# RS1xxxx register map
Vendor: Silicon Lab Inc.; Series: ARMCM4; File version: 1.2
CPU: CM4 r1p0, little endian, MPU, FPU, 6 interrupt priority bits
Registers are 32-bit, read-write, reset 0x0 unless marked. A register's access mark holds for its fields unless they carry their own. Offsets are from the block's base; [hi:lo] are bit positions; {n}, {i} and the like mark numbered series; 'fields as' and 'values as' point back to an identical list.

## QSPI_2 (part 1 of 2) — The queued serial peripheral interface module provides a serial peripheral interface with queued transfer capability
Base 0x12040000
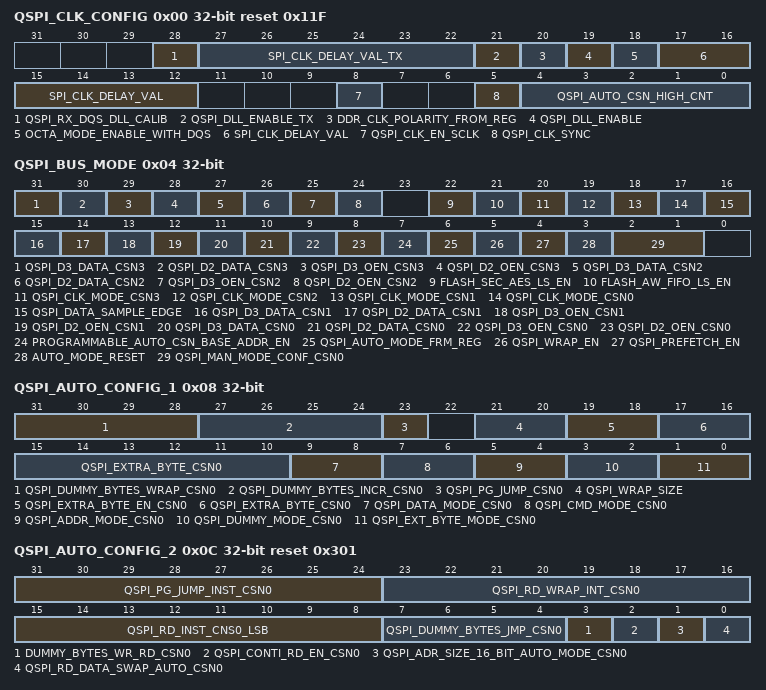
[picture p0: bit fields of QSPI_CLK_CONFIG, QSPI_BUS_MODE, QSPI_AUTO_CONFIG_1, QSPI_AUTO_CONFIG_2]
0x00 QSPI_CLK_CONFIG reset 0x11F — QSPI Clock Configuration Register
  [28] QSPI_RX_DQS_DLL_CALIB — Delay value programmed to TX QSPI DLL in write path. This delay is used to delay the qspi clock output according to the requirement
  [27:22] SPI_CLK_DELAY_VAL_TX — Delay value programmed to TX QSPI DLL in write path. This delay is used to delay the qspi clock output according to the requirement
  [21] QSPI_DLL_ENABLE_TX — Enable for TX QSPI DLL in write path. This is used in M4SS QSPI DDR pads to delay the qspi clock output. 0–DLL is disabled bypassed 1–DLL is enabled
    0=Disable (DLL is disabled/bypassed.); 1=Enable (DLL is enabled)
  [20] DDR_CLK_POLARITY_FROM_REG — Used this bit to sample the data at posedge negedge after interface FFs with internal qspi clock
    0=Disable (Sample at negedge); 1=Enable (Sample at posedge)
  [19] QSPI_DLL_ENABLE — Enable for RX QSPI DLL in read mode.This is used in M4SS QSPI DDR pads to delay the pad clock DQS input
    0=Disable (DLL is disabled/bypassed); 1=Enable (DLL is enabled)
  [18] OCTA_MODE_ENABLE_WITH_DQS — Enables SPI octa mode along with DQS in DDR mode
  [17:12] SPI_CLK_DELAY_VAL — Delay value programmed to RX QSPI DLL on read side. This delay is used to delay the pad clock/DQS according to the requirement
  [8] QSPI_CLK_EN_SCLK — QSPI clock enable for sclock
    0=Disable (Dynamic clock gating is enabled in side QSPI controller); 1=Enable (Full time clock is enabled for QSPI controller.)
  [5] QSPI_CLK_SYNC — If the clock frequency to FLASH(spi_clk) and QSPI(hclk) controller is same,this bit can be set to one to by-pass the syncros results in time consumption
    0=Disable (Sync logic is enabled); 1=Enable (Sync (synchros) logic is bypassed)
  [4:0] QSPI_AUTO_CSN_HIGH_CNT — Minimum SOC clock cycles, during which QSPI auto csn should be high between consecutive CSN assertions
0x04 QSPI_BUS_MODE
  [31] QSPI_D3_DATA_CSN3 — Value of SPI_IO3 in case of dual/single mode for chip select3 (cs_n3). It is used both in Auto and Manual Mode.
  [30] QSPI_D2_DATA_CSN3 — Value of SPI_IO2 in case of dual/single mode for chip select3 (cs_n3). It is used both in Auto and Manual Mode.
  [29] QSPI_D3_OEN_CSN3 — Direction Control for SPI_IO3 in case of dual/single mode for chip select3 (cs_n3). It is used both in Auto and Manual Mode.
  [28] QSPI_D2_OEN_CSN3 — Direction Control for SPI_IO2 in case of dual/single mode for chip select3 (cs_n3). It is used both in Auto and Manual Mode.
  [27] QSPI_D3_DATA_CSN2 — Value of SPI_IO3 in case of dual/single mode for chip select2 (cs_n2). It is used both in Auto and Manual Mode.
  [26] QSPI_D2_DATA_CSN2 — Value of SPI_IO2 in case of dual/single mode for chip select2 (cs_n2). It is used both in Auto and Manual Mode.
  [25] QSPI_D3_OEN_CSN2 — Direction Control for SPI_IO3 in case of dual/single mode for chip select2 (cs_n2). It is used both in Auto and Manual Mode.
  [24] QSPI_D2_OEN_CSN2 — Direction Control for SPI_IO2 in case of dual/single mode for chip select2 (cs_n2). It is used both in Auto and Manual Mode.
  [22] FLASH_SEC_AES_LS_EN — Qspi flash auto write fifo light sleep enable
  [21] FLASH_AW_FIFO_LS_EN — Qspi flash auto write fifo light sleep enable
  [20] QSPI_CLK_MODE_CSN3 — QSPI Clock Mode
    0=Mode 0, QSPI_CLK is low when QSPI_CS is high for chip select3 csn3; 1=Mode 3, QSPI_CLK is high when QSPI_CS is high for chip select3 csn3
  [19] QSPI_CLK_MODE_CSN2 — QSPI Clock Mode
    0=Mode 0 QSPI_CLK is low when QSPI_CS is high for chip select2 csn2; 1=Mode 3 QSPI_CLK is high when QSPI_CS is high for chip select2 csn2
  [18] QSPI_CLK_MODE_CSN1 — QSPI Clock Mode
    0=Mode 0, QSPI_CLK is low when QSPI_CS is high for chip select1 csn1; 1=Mode 3, QSPI_CLK is high when QSPI_CS is high for chip select1 csn1
  [17] QSPI_CLK_MODE_CSN0 — QSPI Clock Mode
    0=Mode 0, QSPI_CLK is low when QSPI_CS is high for chip select0 csn0; 1=Mode 3, QSPI_CLK is high when QSPI_CS is high for chip select0 csn0
  [16] QSPI_DATA_SAMPLE_EDGE — Samples MISO data on clock edges. This should be ZERO for mode3 clock.
    0=Disable (Pos edge of loop back spi_pad_clk. Use for low speed mode (sclk freq =< 40 MHz)); 1=Enable (Neg edge of loop back spi_pad_clk. Use for high speed mode (sclk freq >= 40 MHz))
  [15] QSPI_D3_DATA_CSN1 — Value of SPI_IO3 in case of dual/single mode for chip select1 (cs_n1). It is used both in Auto and Manual Mode.
  [14] QSPI_D2_DATA_CSN1 — Value of SPI_IO2 in case of dual/single mode for chip select1 (cs_n1). It is used both in Auto and Manual Mode.
  [13] QSPI_D3_OEN_CSN1 — Direction Control for SPI_IO3 in case of dual/single mode for chip select1 (cs_n1). It is used both in Auto and Manual Mode.
  [12] QSPI_D2_OEN_CSN1 — Direction Control for SPI_IO2 in case of dual/single mode for chip select1 (cs_n1). It is used both in Auto and Manual Mode.
  [11] QSPI_D3_DATA_CSN0 — Value of SPI_IO3 in case of dual/single mode for chip select0 csn0.It is used both in Auto and Manual Mode
  [10] QSPI_D2_DATA_CSN0 — Value of SPI_IO2 in case of dual/single mode for chip select0 csn0.It is used both in Auto and Manual Mode.
  [9] QSPI_D3_OEN_CSN0 — Direction Control for SPI_IO3 in case of dual/single mode for chip select0 csn0.It is used both in Auto and Manual Mode.
  [8] QSPI_D2_OEN_CSN0 — Direction Control for SPI_IO2 in case of dual/single mode for chip select0 csn0.It is used both in Auto and Manual Mode
  [7] PROGRAMMABLE_AUTO_CSN_BASE_ADDR_EN — Programmable auto csn mode enable
    1=Enable (Programmable auto csn mode is enabled.); 0=Disable (Programmable auto csn mode is diabled)
  [6] QSPI_AUTO_MODE_FRM_REG — QSPI Mode of Operation. This is valid only when HW_CTRLD_QSPI_MODE_CTRL is zero. Before switching from MANUAL to AUTO_MODE, MANUAL should be IDLE. During transition from AUTO_MODE to MANUAL_MODE(After resetting this bit to zero) we have to make sure AUTO mode operations should be completed by checking the STATUS bit in MANUAL_STATUS register[12] (0 - Idle).
    0=Disable (Manual Mode is selected); 1=Enable (Auto Mode is selected.)
  [5] QSPI_WRAP_EN — Model wrap is considered with this bit and uses wrap instruction to read from FLASH, loaded into corresponding auto_config (csn0, csn1) register. Note : Wrap mode is common in AUTO_MODE for both Flashes connected to csn0 and csn1.
    0=Disable (Wrap mode is disabled (AHB WRAP can be used).); 1=Enable (Wrap mode is enabled)
  [4] QSPI_PREFETCH_EN — Pre-fetch of data from the model which is connected to QSPI, automatically with out reading on AHB and is supplied to AHB, when address is matched with AHB read transaction address. Note : Pre-fetch mode is common in AUTO_MODE for both Flashes connected to csn0 and csn1.
    0=Disable (Pre-fetch mode is disabled.); 1=Enable (Pre-fetch mode is enabled)
  [3] AUTO_MODE_RESET — QSPI Auto controller reset. This is not a Self clearing bit
    0=Disable (Auto mode is active); 1=Enable (Auto mode is inactive(In soft-reset). Auto mode FIFO also get reset. Prefetch should be disabled while going to reset. The controller should be in normal (Not a HW_mode) Manual mode.)
  [2:1] QSPI_MAN_MODE_CONF_CSN0 — Configures the QSPI flash for Single/Dual/Quad mode operation in manual mode
    0=Single Mode; 1=Dual Mode; 2=Quad Mode
0x08 QSPI_AUTO_CONFIG_1 (reset mask 0xFF8FFFFF) — QSPI Auto Controller Configuration 1 Register
  [31:28] QSPI_DUMMY_BYTES_WRAP_CSN0 — Specifies the number of dummy bytes 0 to 7 for the selected SPI mode in case of wrap instruction
  [27:24] QSPI_DUMMY_BYTES_INCR_CSN0 — Specifies the number of dummy bytes 0 to 7 for the selected SPI mode
  [23] QSPI_PG_JUMP_CSN0 — Index Jump instruction
    0=Disable (Do not use Index jump instruction); 1=Enable (Use Index jump instruction specified by QSPI_PG_JUMP_INST)
  [21:20] QSPI_WRAP_SIZE — Qspi auto wrap size
  [19:18] QSPI_EXTRA_BYTE_EN_CSN0 — Value of the extra byte to be transmitted, if the extra byte mode is enabled
    0=Not transmit byte (Do not transmit extra byte.); 1=Transmit byte (Transmit Extra byte after address phase); 2=Transmit first nibble (Transmit only first nibble of the byte and maintain Hi-Z on the IO bus for next nibble)
  [17:10] QSPI_EXTRA_BYTE_CSN0 — Value of the extra byte to be transmitted, if the extra byte mode is enabled
  [9:8] QSPI_DATA_MODE_CSN0 — Mode of operation of QSPI in DATA phase
    0=SPI; 1=Dual SPI; 2=Quad SPI
  [7:6] QSPI_CMD_MODE_CSN0 — Mode of operation of QSPI in instruction phase
    0=SPI; 1=Dual SPI; 2=Quad SPI
  [5:4] QSPI_ADDR_MODE_CSN0 — Mode of operation of QSPI in instruction phase
    0=SPI; 1=Dual SPI; 2=Quad SPI
  [3:2] QSPI_DUMMY_MODE_CSN0 — Mode of operation of QSPI in instruction phase
    0=SPI; 1=Dual SPI; 2=Quad SPI
  [1:0] QSPI_EXT_BYTE_MODE_CSN0 — Mode of operation of QSPI in the extra byte phase
    0=SPI; 1=Dual SPI; 2=Quad SPI
0x0C QSPI_AUTO_CONFIG_2 reset 0x301 — QSPI Auto Controller Configuration 2 Register
  [31:24] QSPI_PG_JUMP_INST_CSN0 — Read instruction to be used, when Page jump is to be used
  [23:16] QSPI_RD_WRAP_INT_CSN0 — Read instruction to be used, when wrap mode is supported by QSPI flash
  [15:8] QSPI_RD_INST_CNS0_LSB — Read instruction LS byte to be used for the selected SPI modes and when wrap is not needed or supported.
  [7:4] QSPI_DUMMY_BYTES_JMP_CSN0 — Dummy cycles to be selected in case of JUMP
  [3] DUMMY_BYTES_WR_RD_CSN0 — Dummy bytes to the model to be read or to be write
    0=Disable (Dummy bytes will be read); 1=Enable (Dummy bytes to be write.)
  [2] QSPI_CONTI_RD_EN_CSN0 — Continuous read enable bit
    0=Disable (Continuous read disabled.); 1=Enable (Continuous read enabled.)
  [1] QSPI_ADR_SIZE_16_BIT_AUTO_MODE_CSN0 — Bit address sent to model
    0=Disable (24 bit address is sent to model); 1=Enable (16 Bit address is sent to model)
  [0] QSPI_RD_DATA_SWAP_AUTO_CSN0 — Auto read data
    0=Disable (Do not swap the read data in auto mode); 1=Enable (Swap the auto read data in auto mode)
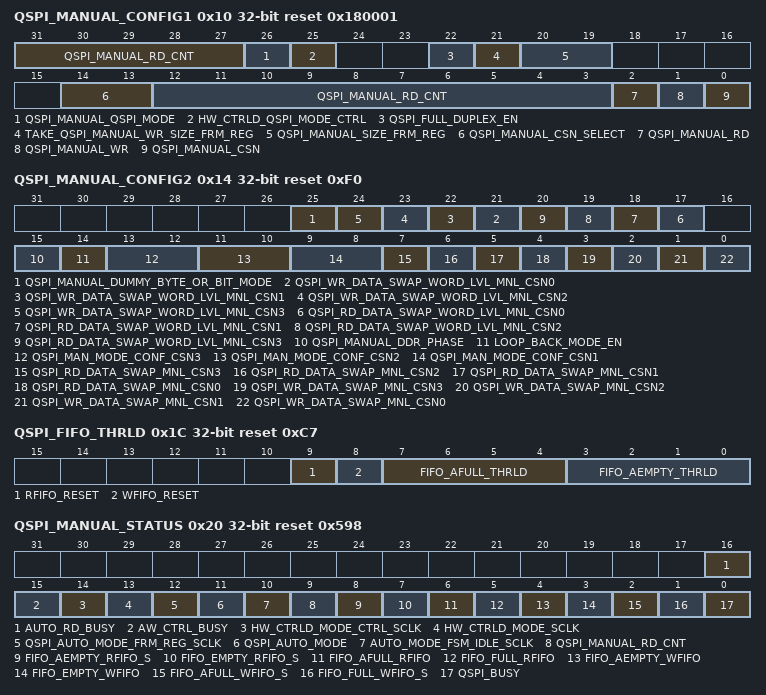
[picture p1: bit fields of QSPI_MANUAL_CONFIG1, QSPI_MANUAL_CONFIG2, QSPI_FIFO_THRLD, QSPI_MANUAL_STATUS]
0x10 QSPI_MANUAL_CONFIG1 reset 0x180001 — QSPI Manual Configuration 1 Register
  [31:27] QSPI_MANUAL_RD_CNT — Indicates total number of bytes or bits (depending on Qspi_manual_dummy_byte_or_bit_mode bit) to be read along with 12:3 bits of this register. Maximum length supported is 32k bytes.
  [26] QSPI_MANUAL_QSPI_MODE — Internally the priority is given to manual mode
    0=Disable (SPI mode); 1=Enable (Host SPI mode.)
  [25] HW_CTRLD_QSPI_MODE_CTRL — Hardware controlled qspi mode in between AUTO and manual
    0=Disable (Hardware control is disabled); 1=Enable (Hardware control is enabled.)
  [22] QSPI_FULL_DUPLEX_EN — Full duplex mode enable.
    0=Disable (Full duplex mode disabled.); 1=Enable (Full duplex mode enabled)
  [21] TAKE_QSPI_MANUAL_WR_SIZE_FRM_REG — QSPI take write size
    0=Disable (No action. Takes write size from fifo); 1=Enable (Take write size from Manual config register1)
  [20:19] QSPI_MANUAL_SIZE_FRM_REG — Manual reads and manual writes(If take_manual_size_from_reg bit is 1)
    0=1 Byte (8 – bit mode); 1=2 Bytes (16 – bit mode); 2=3 Bytes (24 – bit mode); 3=4 Bytes (32 – bit mode)
  [14:13] QSPI_MANUAL_CSN_SELECT — Indicates which CSn is valid. Can be programmable in manual mode. Note : In auto mode csn select is decoded from the address itself, AHB_addr [25:24].
  [12:3] QSPI_MANUAL_RD_CNT — Indicates total number of bytes to be read along with [31:27] bits of this register.Maximum length supported is 32k bytes
  [2] QSPI_MANUAL_RD — Read enable for manual mode when CS is low
  [1] QSPI_MANUAL_WR — Write enable for manual mode when CS is low
  [0] QSPI_MANUAL_CSN — SPI CS in manual mode
0x14 QSPI_MANUAL_CONFIG2 reset 0xF0 (reset mask 0xFFF) — QSPI Manual Configuration 2 Register
  [25] QSPI_MANUAL_DUMMY_BYTE_OR_BIT_MODE — Indicates qspi_manual_rd_cnt values are dummy bytes or bits in manual mode.It is used to provide proper dummy cycles in manual read mode.
    1=Enable (Dummy bits mode); 0=Disable (Dummy bytes mode)
  [n+21] QSPI_WR_DATA_SWAP_WORD_LVL_MNL_CSN{n} (n=0..3) — Set this bit for write data byte swapping within the word. It is valid only for octa ddr mode. It is valid for csn{n}.
  [n+17] QSPI_RD_DATA_SWAP_WORD_LVL_MNL_CSN{n} (n=0..3) — Set this bit for read data byte swapping within the word. It is valid only for octa ddr mode. It is valid for csn{n}.
  [15] QSPI_MANUAL_DDR_PHASE — DDR operations can be performed even in manual mode
    1=Enable (Manual mode DDR operation enabled.); 0=Disable (Manual mode DDR operation disabled)
  [14] LOOP_BACK_MODE_EN — Internal loop back test mode. When this is enabled, what ever data driven out will be sampled in to DOUT fifo.
  [13:12] QSPI_MAN_MODE_CONF_CSN3 — Configures the QSPI flash for Single or Dual or Quad mode operation in manual mode for chip select3 csn3
    0=Single; 1=Dual; 2=Quad
  [11:10] QSPI_MAN_MODE_CONF_CSN2 — Configures the QSPI flash for Single or Dual or Quad mode operation in manual mode for chip select2 csn2
    0=Single; 1=Dual; 2=Quad
  [9:8] QSPI_MAN_MODE_CONF_CSN1 — Configures the QSPI flash for Single/Dual/Quad mode operation in manual mode for chip select1 csn1
    0=Single; 1=Dual; 2=Quad
  [7] QSPI_RD_DATA_SWAP_MNL_CSN3 — Swap the read data inside the QSPIcontroller itself
    0=Disable (Manual read data swap is disabled for csn3); 1=Enable (Manual read data swap is enabled for csn3)
  [6] QSPI_RD_DATA_SWAP_MNL_CSN2 — Swap the read data inside the QSPIcontroller it-self
    0=Disable (Manual read data swap is disabled for csn2); 1=Enable (Manual read data swap is enabled for csn2)
  [5] QSPI_RD_DATA_SWAP_MNL_CSN1 — Swap the read data inside the QSPIcontroller itself.
    0=Disable (Manual read data swap is disabled for csn1); 1=Enable (Manual read data swap is enabled for csn1)
  [4] QSPI_RD_DATA_SWAP_MNL_CSN0 — Swap the read data inside the QSPIcontroller it self.
    0=Disable (Manual read data swap is disabled for csn0.); 1=Enable (Manual read data swap is enabled for csn0.)
  [3] QSPI_WR_DATA_SWAP_MNL_CSN3 — Swap the write data inside the QSPI controller itself.
    0=Disable (Manual write data swap is disabled for csn3.); 1=Enable (Manual write data swap is enabled for csn3.)
  [2] QSPI_WR_DATA_SWAP_MNL_CSN2 — Swap the write data inside the QSPI controller itself.
    0=Disable (Manual write data swap is disabled for csn2.); 1=Enable (Manual write data swap is enabled for csn2.)
  [1] QSPI_WR_DATA_SWAP_MNL_CSN1 — Swap the write data inside the QSPI controller it-self.
    0=Disable (Manual write data swap is disabled for csn1.); 1=Enable (Manual write data swap is enabled for csn1.)
  [0] QSPI_WR_DATA_SWAP_MNL_CSN0 — Swap the write data inside the QSPI controller it-self
    0=Disable (Manual write data swap is disabled for csn0.); 1=Enable (Manual write data swap is enabled for csn0.)
0x1C QSPI_FIFO_THRLD reset 0xC7 (reset mask 0x1FF) — QSPI FIFO Threshold Register
  [9] RFIFO_RESET — Read fifo reset
  [8] WFIFO_RESET — Write fifo reset
  [7:4] FIFO_AFULL_THRLD — FIFO almost full threshold
  [3:0] FIFO_AEMPTY_THRLD — FIFO almost empty threshold
0x20 QSPI_MANUAL_STATUS ro reset 0x598 (reset mask 0x7FFF)
  [16] AUTO_RD_BUSY — Auto read busy indication.
  [15] AW_CTRL_BUSY — Auto write busy indication.
  [14] HW_CTRLD_MODE_CTRL_SCLK — HW_CTRLD_MODE status
    0=Disable (HW_CTRL_MODE is disabled.); 1=Enable (HW_CTRL_MODE is enabled)
  [13] HW_CTRLD_MODE_SCLK — QSPI mode status in HW_CTRLD_MODE
    0=Disable (QSPI controller is in MANUAL mode.); 1=Enable (QSPI controller is working in AUTO MODE.)
  [12] QSPI_AUTO_MODE_FRM_REG_SCLK — QSPI auto mode status. Valid only when HW_CTRLD_QSPI_MODE_CTRL is zero.
    0=Disable (QSPI controller is hot coded to manual mode operations.); 1=Enable (QSPI controller is hot coded to AUTO mode operations)
  [11] QSPI_AUTO_MODE — QSPI controller status.
    0=Disable (QSPI controller is in manual mode.); 1=Enable (QSPI controller is in auto mode.)
  [10] AUTO_MODE_FSM_IDLE_SCLK — Auto mode idle signal to track auto controller is busy or idle.
    0=Disable (Auto mode is busy); 1=Enable (Auto mode is idle)
  [9] QSPI_MANUAL_RD_CNT — This is a result of 10 bits ORing counter
    0=Disable (No read transactions are in pending); 1=Enable (Read transactions are in pending ( to be done))
  [8] FIFO_AEMPTY_RFIFO_S — Status indication for Rfifo in manual mode
  [7] FIFO_EMPTY_RFIFO_S — Status indication for Rfifo in manual mode
  [6] FIFO_AFULL_RFIFO — Status indication for Rfifo in manual mode
  [5] FIFO_FULL_RFIFO — Status indication for Rfifo in manual mode
  [4] FIFO_AEMPTY_WFIFO — Status indication for Wfifo in manual mode
  [3] FIFO_EMPTY_WFIFO — Status indication for Wfifo in manual mode
  [2] FIFO_AFULL_WFIFO_S — Status indication for Wfifo in manual mode
  [1] FIFO_FULL_WFIFO_S — Status indication for Wfifo in manual mode
  [0] QSPI_BUSY — State of Manual mode.
    0=Disable (QSPI controller is IDLE in Manual mode.); 1=Enable (A read, write or dummy cycle operation is in process in manual mode.)
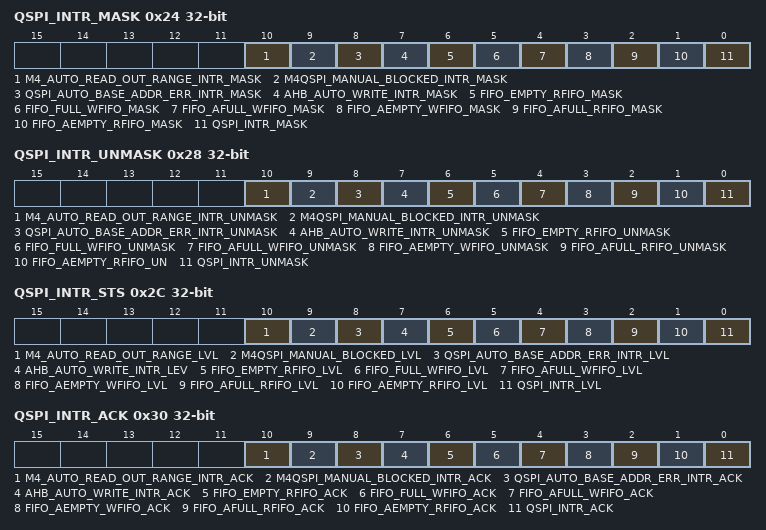
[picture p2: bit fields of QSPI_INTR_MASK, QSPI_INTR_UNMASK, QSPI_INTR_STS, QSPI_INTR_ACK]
0x24 QSPI_INTR_MASK (reset mask 0x6F) — QSPI Interrupt Mask Register
  [10] M4_AUTO_READ_OUT_RANGE_INTR_MASK — Rising interrupt when M4 QSPI tries to read TA locations in Common flash mode (3). This bit is a mask for this interrupt.
  [9] M4QSPI_MANUAL_BLOCKED_INTR_MASK — Rising interrupt when M4 QSPI tries to do manual mode transactions in Common flash mode (3). This bit is a mask for this interrupt.
  [8] QSPI_AUTO_BASE_ADDR_ERR_INTR_MASK — Rising interrupt when no csn is selected using programmable auto base address. This bit is a mask for this interrupt.
  [7] AHB_AUTO_WRITE_INTR_MASK — Rising interrupt for any auto write operation on AHB bus. This bit is a mask for this interrupt
  [6] FIFO_EMPTY_RFIFO_MASK — Read FIFO empty interrupt mask
    0=Disable (Do not touch); 1=Enable (Read fifo is empty intr mask)
  [5] FIFO_FULL_WFIFO_MASK — Write FIFO full interrupt mask
    2=Disable (Do not touch); 1=Enable (write fifo full intr mask)
  [4] FIFO_AFULL_WFIFO_MASK — Write FIFO almost full interrupt mask
    0=Disable (Do not touch); 1=Enable (Write fifo almost full intr mask)
  [3] FIFO_AEMPTY_WFIFO_MASK — Write FIFO almost empty interrupt mask
    0=Disable (Do not touch); 1=Enable (write fifo almost empty intr mask.)
  [2] FIFO_AFULL_RFIFO_MASK — Read FIFO almost full interrupt mask
    0=Disable (Do not touch); 1=Enable (read fifo almost full intr mask)
  [1] FIFO_AEMPTY_RFIFO_MASK — Read FIFO almost empty interrupt mask
    0=Disable (Do not touch); 1=Enable (Read fifo almost empty intr mask.)
  [0] QSPI_INTR_MASK — Interrupt Status bit
    0=Disable (Do not touch); 1=Enable (mask the qspi intr)
0x28 QSPI_INTR_UNMASK (reset mask 0x7F) — QSPI Interrupt Unmask Register
  [10] M4_AUTO_READ_OUT_RANGE_INTR_UNMASK — Rising interrupt when M4 QSPI tries to read TA locations in Common flash mode (3). This bit is a unmask for this interrupt.
  [9] M4QSPI_MANUAL_BLOCKED_INTR_UNMASK — Rising interrupt when M4 QSPI tries to do manual mode transactions in Common flash mode (3). This bit is a unmask for this interrupt.
  [8] QSPI_AUTO_BASE_ADDR_ERR_INTR_UNMASK — Rising interrupt when M4 QSPI tries to do manual mode transactions in Common flash mode (3). This bit is a unmask for this interrupt.
  [7] AHB_AUTO_WRITE_INTR_UNMASK — Rising interrupt for any auto write operation on AHB bus. This bit is a unmask for this interrupt.
  [6] FIFO_EMPTY_RFIFO_UNMASK — Read FIFO empty interrupt unamsk
    0=Disable (Do not touch); 1=Enable (Read fifo is empty intr unmask)
  [5] FIFO_FULL_WFIFO_UNMASK — Write FIFO full interrupt unamsk
    4=Disable (Do not touch); 3=Enable (write fifo full intr unmask)
  [4] FIFO_AFULL_WFIFO_UNMASK — Write FIFO almost full interrupt unamsk
    0=Disable (Do not touch); 1=Enable (Write fifo almost full intr unmask.)
  [3] FIFO_AEMPTY_WFIFO_UNMASK — Write FIFO almost empty interrupt unamsk
    0=Disable (Do not touch); 1=Enable (write fifo almost empty intr unmask)
  [2] FIFO_AFULL_RFIFO_UNMASK — Read FIFO almost full interrupt unamsk
    0=Disable (Do not touch); 1=Enable (read fifo almost full intr unmask.)
  [1] FIFO_AEMPTY_RFIFO_UN — Read FIFO almost empty interrupt unamsk
    0=Disable (Do not touch); 1=Enable (Read fifo almost empty intr unmask)
  [0] QSPI_INTR_UNMASK — Interrupt Status bit
    0=Disable (Do not touch); 1=Enable (unmask the qspi intr)
0x2C QSPI_INTR_STS ro (reset mask 0x7F) — QSPI Interrupt Status Register
  [10] M4_AUTO_READ_OUT_RANGE_LVL — Rising interrupt when M4 QSPI tries to read TA locations in Common flash mode (3).
  [9] M4QSPI_MANUAL_BLOCKED_LVL — Rising interrupt when M4 QSPI tries to do manual mode transactions in Common flash mode (3).
  [8] QSPI_AUTO_BASE_ADDR_ERR_INTR_LVL — Rising interrupt when no csn is selected using programmable auto base address.
  [7] AHB_AUTO_WRITE_INTR_LEV — rising interrupt for any auto write operation on AHB bus.
  [6] FIFO_EMPTY_RFIFO_LVL — Read FIFO reached empty threshold
    0=Disable (Read FIFO is not empty); 1=Enable (Read FIFO is empty)
  [5] FIFO_FULL_WFIFO_LVL — Write FIFO reached full threshold
    0=Disable (Write fifo not got full); 1=Enable (write fifo got full.)
  [4] FIFO_AFULL_WFIFO_LVL — Write FIFO reached almost full threshold
    0=Disable (write FIFO not reached almost full threshold); 1=Enable (Write FIFO reached almost full threshold)
  [3] FIFO_AEMPTY_WFIFO_LVL — Write FIFO reached almost empty threshold
    0=Disable (write FIFO not reached almost full threshold.); 1=Enable (write FIFO reached almost empty threshold.)
  [2] FIFO_AFULL_RFIFO_LVL — Read FIFO reached almost full threshold
    0=Disable (read FIFO do not reached almost full threshold); 1=Enable (read FIFO reached almost full threshold)
  [1] FIFO_AEMPTY_RFIFO_LVL — Read FIFO reached almost empty threshold
    0=Disable (Read fifo does not reached almost empty threshold); 1=Enable (Read fifo reached almost empty threshold)
  [0] QSPI_INTR_LVL — Interrupt Status bit
    0=Disable (no interrupt); 1=Enable (qspi raised a interrupt)
0x30 QSPI_INTR_ACK (reset mask 0x7F) — QSPI Interrupt Acknowledge Register
  [10] M4_AUTO_READ_OUT_RANGE_INTR_ACK — Rising interrupt when M4 QSPI tries to read TA locations in Common flash mode (3). This bit is an ack for this interrupt.
  [9] M4QSPI_MANUAL_BLOCKED_INTR_ACK — Rising interrupt when M4 QSPI tries to do manual mode transactions in Common flash mode (3).This bit is an ack for this interrupt.
  [8] QSPI_AUTO_BASE_ADDR_ERR_INTR_ACK wo — Rising interrupt when no csn is selected using programmable auto base address. This bit is an ack for this interrupt.
  [7] AHB_AUTO_WRITE_INTR_ACK wo — Rising interrupt for any auto write operation on AHB bus. This bit is an ack for this interrupt.
  [6] FIFO_EMPTY_RFIFO_ACK wo — Read fifo empty interrupt unmask
    values as QSPI_INTR_UNMASK.FIFO_EMPTY_RFIFO_UNMASK
  [5] FIFO_FULL_WFIFO_ACK wo — Write fifo full interrupt unmask
    0=Disable (Do not touch); 1=Enable (write fifo full intr unmask)
  [4] FIFO_AFULL_WFIFO_ACK wo — Write fifo almost full interrupt unmask
    values as QSPI_INTR_UNMASK.FIFO_AFULL_WFIFO_UNMASK
  [3] FIFO_AEMPTY_WFIFO_ACK wo — Write fifo almost empty interrupt unmask
    0=Disable (Do not touch); 1=Enable (write fifo almost empty intr unmask.)
  [2] FIFO_AFULL_RFIFO_ACK wo — Read fifo almost full interrupt unmask
    values as QSPI_INTR_UNMASK.FIFO_AFULL_RFIFO_UNMASK
  [1] FIFO_AEMPTY_RFIFO_ACK wo — Read fifo almost empty interrupt unmask
    values as QSPI_INTR_UNMASK.FIFO_AEMPTY_RFIFO_UN
  [0] QSPI_INTR_ACK wo — Interrupt Status bit
    0=Disable (Do not touch); 1=Enable (unmask the qspi intr.)
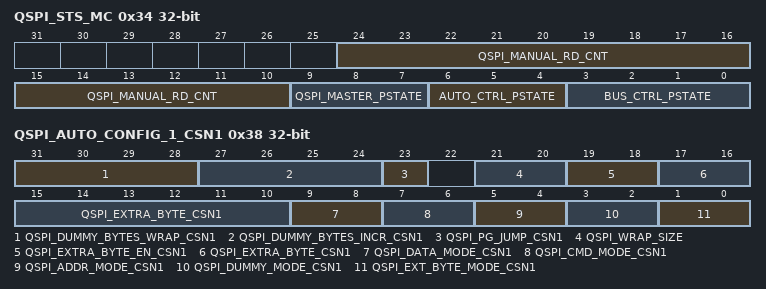
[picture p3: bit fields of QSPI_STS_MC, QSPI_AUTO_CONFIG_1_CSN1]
0x34 QSPI_STS_MC ro (reset mask 0x6FF) — QSPI State Machine Monitor Register
  [24:10] QSPI_MANUAL_RD_CNT — Qspi manual read counter value
  [9:7] QSPI_MASTER_PSTATE — Qspi master present state
  [6:4] AUTO_CTRL_PSTATE — Auto controller present state
  [3:0] BUS_CTRL_PSTATE — Bus controller present state
0x38 QSPI_AUTO_CONFIG_1_CSN1 (reset mask 0x87FFFF) — QSPI Auto Controller Configuration 1 CSN1 Register
  [31:28] QSPI_DUMMY_BYTES_WRAP_CSN1 ro — Specifies the number of dummy bytes 0 to 7 for the selected SPI mode in case of wrap instruction.
  [27:24] QSPI_DUMMY_BYTES_INCR_CSN1 ro — Specifies the number of dummy bytes 0 to 7 for the selected SPI mode.
  [23] QSPI_PG_JUMP_CSN1 wo — QSPI index jump instruction
    0=Disable (Do not use Index jump instruction.); 1=Enable (Use Index jump instruction specified by QSPI_PG_JUMP_INST)
  [21:20] QSPI_WRAP_SIZE — Qspi auto wrap size
  [19:18] QSPI_EXTRA_BYTE_EN_CSN1 — Mode of operation of QSPI in DATA phase.
    0=Not transmit (Do not transmit extra byte.); 1=Transmit Extra byte after address phase; 2=Transmit nibble (Transmit only first nibble of the byte and maintain Hi-Z on the IO bus for next nibble.)
  [17:10] QSPI_EXTRA_BYTE_CSN1 — Value of the extra byte to be transmitted, if the extra byte mode is enabled.
  [9:8] QSPI_DATA_MODE_CSN1 — Mode of operation of QSPI in DATA phase.
    0=SPI; 1=Dual SPI; 2=Quad SPI
  [7:6] QSPI_CMD_MODE_CSN1 — Mode of operation of QSPI in instruction phase.
    0=SPI; 1=Dual SPI; 2=Quad SPI
  [5:4] QSPI_ADDR_MODE_CSN1 — Mode of operation of QSPI in instruction phase.
    0=SPI; 1=Dual SPI; 2=Quad SPI
  [3:2] QSPI_DUMMY_MODE_CSN1 — Mode of operation of QSPI in instruction phase
    0=SPI; 1=Dual SPI; 2=Quad SPI
  [1:0] QSPI_EXT_BYTE_MODE_CSN1 — Mode of operation of QSPI in instruction phase.
    0=SPI; 1=Dual SPI; 2=Quad SPI
